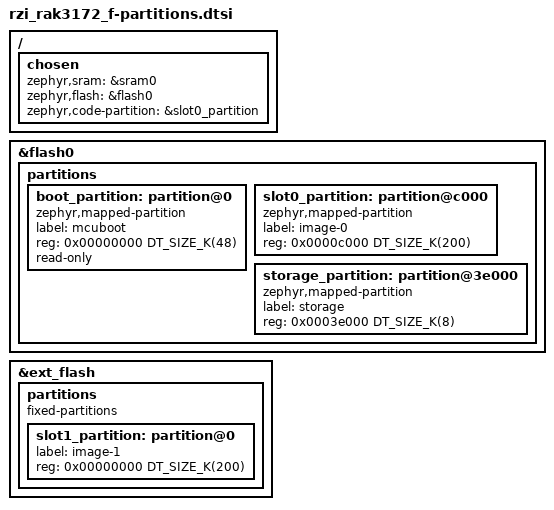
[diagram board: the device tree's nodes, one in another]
/* SPDX-FileCopyrightText: Copyright (c) 2026 RAKwireless */
/* SPDX-License-Identifier: Apache-2.0 */
/*
 * rzi_rak3172_f flash map.
 *
 * Internal STM32WLE5 flash is 256 KiB and holds the running image:
 * 48K boot + 200K slot0 + 8K storage. MCUboot is larger than on
 * RAK3372 because it has to read the MX25L400. The 512 KiB NOR holds
 * slot1 at the same size as slot0. MCUboot copies slot1 over slot0
 * (overwrite). LoRaWAN FUOTA writes the signed image to image-1.
 */

/ {
	chosen {
		zephyr,sram = &sram0;
		zephyr,flash = &flash0;
		zephyr,code-partition = &slot0_partition;
	};
};

&flash0 {
	partitions {
		ranges;
		#address-cells = <1>;
		#size-cells = <1>;

		boot_partition: partition@0 {
			compatible = "zephyr,mapped-partition";
			label = "mcuboot";
			reg = <0x00000000 DT_SIZE_K(48)>;
			read-only;
		};

		slot0_partition: partition@c000 {
			compatible = "zephyr,mapped-partition";
			label = "image-0";
			reg = <0x0000c000 DT_SIZE_K(200)>;
		};

		storage_partition: partition@3e000 {
			compatible = "zephyr,mapped-partition";
			label = "storage";
			reg = <0x0003e000 DT_SIZE_K(8)>;
		};
	};
};

&ext_flash {
	partitions {
		compatible = "fixed-partitions";
		#address-cells = <1>;
		#size-cells = <1>;

		slot1_partition: partition@0 {
			label = "image-1";
			reg = <0x00000000 DT_SIZE_K(200)>;
		};
	};
};
